# DA1469x register map
Vendor: Dialog; Series: DA1469x; File version: 1.2
CPU: CM33 r1p0, little endian, no MPU, FPU, 3 interrupt priority bits
Registers are 32-bit, read-write, reset 0x0 unless marked. A register's access mark holds for its fields unless they carry their own. Offsets are from the block's base; [hi:lo] are bit positions; {n}, {i} and the like mark numbered series.

## DCDC — DCDC registers
Base 0x50000300
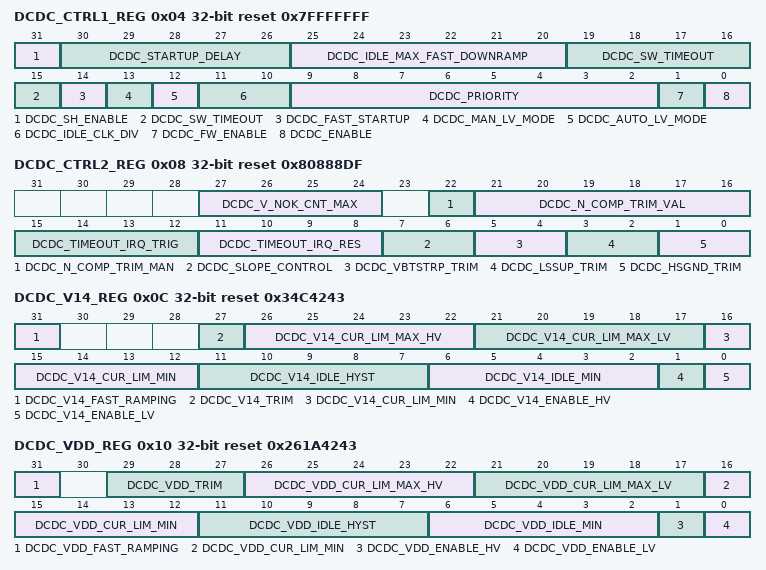
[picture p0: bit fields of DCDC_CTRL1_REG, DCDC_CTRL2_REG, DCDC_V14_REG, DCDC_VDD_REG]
0x04 DCDC_CTRL1_REG reset 0x7FFFFFFF (reset mask 0x7FFFFFFF) — DCDC First Control Register
  [31] DCDC_SH_ENABLE — Enables sample and hold circuit in output comparators.
  [30:26] DCDC_STARTUP_DELAY — Delay between turning bias on and converter becoming active 0 - 31 us, 1 us step size
  [25:20] DCDC_IDLE_MAX_FAST_DOWNRAMP — Maximum output idle time for fast current limit downramping. 0 - 7875 ns, 125 ns step size
  [19:15] DCDC_SW_TIMEOUT — P and N switch timeout, if switch is closed longer than this a timeout is generated and the FSM is forced to the next state Writing 0 disables timeout functionality 62.5 - 1937.5 ns, 62.5 ns step size
  [14] DCDC_FAST_STARTUP — Set current limit to maximum during initial startup
  [13] DCDC_MAN_LV_MODE — Manually activates low voltage settings
  [12] DCDC_AUTO_LV_MODE — Switches to low voltage settings when battery voltage drops below 2.5 V
  [11:10] DCDC_IDLE_CLK_DIV — Idle Clock Divider 00 = 2 01 = 4 10 = 8 11 = 16
  [9:2] DCDC_PRIORITY — Charge priority register (4x 2 bit ID) Charge sequence is [1:0] > [3:2] > [5:4] > [7:6] V14 = 00 V18 = 01 VDD = 10 V18P = 11
  [1] DCDC_FW_ENABLE — Freewheel switch enable
  [0] DCDC_ENABLE — Enable setting for DCDC converter
0x08 DCDC_CTRL2_REG reset 0x80888DF — DCDC Second Control Register
  [27:24] DCDC_V_NOK_CNT_MAX — Maximum number of V_NOK events on an output before V_AVAILABLE is reset
  [22] DCDC_N_COMP_TRIM_MAN — Enables manual trimming for N side comparator
  [21:16] DCDC_N_COMP_TRIM_VAL — Manual trim value for N side comparator Signed magnitude representation 011111 = +13 mV 000000 = 100000 = -22 mV 111111 = -56 mV
  [15:12] DCDC_TIMEOUT_IRQ_TRIG — Number of timeout events before timeout interrupt is generated
  [11:8] DCDC_TIMEOUT_IRQ_RES — Number of successive non-timed out charge events required to clear timeout event counter
  [7:6] DCDC_SLOPE_CONTROL — Sets strength of N and P switch drivers
  [5:4] DCDC_VBTSTRP_TRIM — Trim bootstrap voltage V = 1.6 V + 100 mV * N
  [3:2] DCDC_LSSUP_TRIM — Trim low side supply voltage V = 2 V + 300 mV * N
  [1:0] DCDC_HSGND_TRIM — Trim high side ground V = VBAT - (2 V + 400 mV * N)
0x0C DCDC_V14_REG reset 0x34C4243 (reset mask 0x7FFFFFFF) — DCDC V14 Control Register
  [31] DCDC_V14_FAST_RAMPING — Fast current ramping (improves response time at the cost of more ripple)
  [27] DCDC_V14_TRIM — Output voltage trim Steps of 25 mV
  [26:22] DCDC_V14_CUR_LIM_MAX_HV — Mximum current limit (high battery voltage mode) I = 30 mA * (1 + N)
  [21:17] DCDC_V14_CUR_LIM_MAX_LV — Maximum current limit (low battery voltage mode) I = 30 mA * (1 + N)
  [16:12] DCDC_V14_CUR_LIM_MIN — Minimum current limit I = 30 mA * (1 + N)
  [11:7] DCDC_V14_IDLE_HYST — Idle time hysteresis 0 - 3875 ns, 125 ns step size IDLE_MAX = IDLE_MIN + IDLE_HYST Maximum idle time before decreasing CUR_LIM
  [6:2] DCDC_V14_IDLE_MIN — Minimum idle time 0 - 3875 ns, 125 ns step size Minimum idle time, CUR_LIM is increased if this limit is not reached
  [1] DCDC_V14_ENABLE_HV — Output enable (high battery voltage mode) 0 = Disabled 1 = Enabled
  [0] DCDC_V14_ENABLE_LV — Output enable (low battery voltage mode) 0 = Disabled 1 = Enabled
0x10 DCDC_VDD_REG reset 0x261A4243 (reset mask 0x7FFFFFFF) — DCDC VDD Control Register
  [31] DCDC_VDD_FAST_RAMPING — Fast current ramping (improves response time at the cost of more ripple)
  [29:27] DCDC_VDD_TRIM — Output voltage trim Steps of 25 mV
  [26:22] DCDC_VDD_CUR_LIM_MAX_HV — Maximum current limit (high battery voltage mode) I = 30 mA * (1 + N)
  [21:17] DCDC_VDD_CUR_LIM_MAX_LV — Maximum current limit (low battery voltage mode) I = 30 mA * (1 + N)
  [16:12] DCDC_VDD_CUR_LIM_MIN — Minimum current limit I = 30 mA * (1 + N)
  [11:7] DCDC_VDD_IDLE_HYST — Idle time hysteresis 0 - 3875 ns, 125 ns step size IDLE_MAX = IDLE_MIN + IDLE_HYST Maximum idle time before decreasing CUR_LIM
  [6:2] DCDC_VDD_IDLE_MIN — Minimum idle time 0 - 3875 ns, 125 ns step size Minimum idle time, CUR_LIM is increased if this limit is not reached
  [1] DCDC_VDD_ENABLE_HV — Output enable (high battery voltage mode) 0 = Disabled 1 = Enabled
  [0] DCDC_VDD_ENABLE_LV — Output enable (low battery voltage mode) 0 = Disabled 1 = Enabled
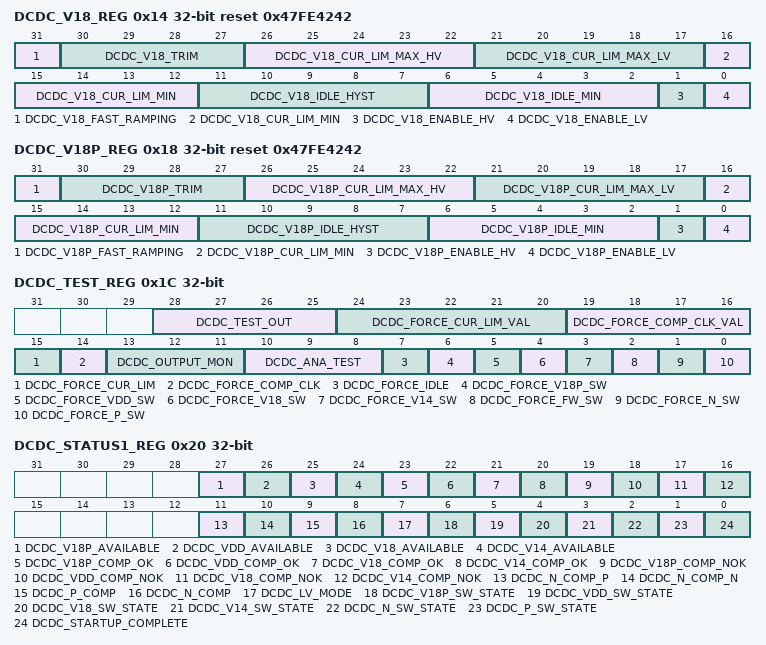
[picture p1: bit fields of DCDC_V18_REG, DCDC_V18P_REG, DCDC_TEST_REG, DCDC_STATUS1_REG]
0x14 DCDC_V18_REG reset 0x47FE4242 (reset mask 0x7FFFFFFF) — DCDC V18 Control Register
  [31] DCDC_V18_FAST_RAMPING — Fast current ramping (improves response time at the cost of more ripple)
  [30:27] DCDC_V18_TRIM — Output voltage trim Steps of 25 mV
  [26:22] DCDC_V18_CUR_LIM_MAX_HV — Maximum current limit (high battery voltage mode) I = 30 mA * (1 + N)
  [21:17] DCDC_V18_CUR_LIM_MAX_LV — Maximum current limit (low battery voltage mode) I = 30 mA * (1 + N)
  [16:12] DCDC_V18_CUR_LIM_MIN — Minimum current limit I = 30 mA * (1 + N)
  [11:7] DCDC_V18_IDLE_HYST — Idle time hysteresis 0 - 3875 ns, 125 ns step size IDLE_MAX = IDLE_MIN + IDLE_HYST Maximum idle time before decreasing CUR_LIM
  [6:2] DCDC_V18_IDLE_MIN — Minimum idle time 0 - 3875 ns, 125 ns step size Minimum idle time, CUR_LIM is increased if this limit is not reached
  [1] DCDC_V18_ENABLE_HV — Output enable (high battery voltage mode) 0 = Disabled 1 = Enabled
  [0] DCDC_V18_ENABLE_LV — Output enable (low battery voltage mode) 0 = Disabled 1 = Enabled
0x18 DCDC_V18P_REG reset 0x47FE4242 (reset mask 0x7FFFFFFF) — DCDC V18P Control Register
  [31] DCDC_V18P_FAST_RAMPING — Fast current ramping (improves response time at the cost of more ripple)
  [30:27] DCDC_V18P_TRIM — Output voltage trim Steps of 25 mV
  [26:22] DCDC_V18P_CUR_LIM_MAX_HV — Maximum current limit (high battery voltage mode) I = 30 mA * (1 + N)
  [21:17] DCDC_V18P_CUR_LIM_MAX_LV — Maximum current limit (low battery voltage mode) I = 30 mA * (1 + N)
  [16:12] DCDC_V18P_CUR_LIM_MIN — Minimum current limit I = 30 mA * (1 + N)
  [11:7] DCDC_V18P_IDLE_HYST — Idle time hysteresis 0 - 3875 ns, 125 ns step size IDLE_MAX = IDLE_MIN + IDLE_HYST Maximum idle time before decreasing CUR_LIM
  [6:2] DCDC_V18P_IDLE_MIN — Minimum idle time 0 - 3875 ns, 125 ns step size Minimum idle time, CUR_LIM is increased if this limit is not reached
  [1] DCDC_V18P_ENABLE_HV — Output enable (high battery voltage mode) 0 = Disabled 1 = Enabled
  [0] DCDC_V18P_ENABLE_LV — Output enable (low battery voltage mode) 0 = Disabled 1 = Enabled
0x1C DCDC_TEST_REG — DCDC Test Register
  [28:25] DCDC_TEST_OUT — Selects which register appears on the test mode pins 0 = None 1 = DCDC_STATUS_1 High Bits 2 = DCDC_STATUS_1 Low Bits 3 = DCDC_STATUS_2 High Bits 4 = DCDC_STATUS_2 Low Bits 5 = DCDC_STATUS_3 High Bits 6 = DCDC_STATUS_3 Low Bits 7 = DCDC_STATUS_4 Low Bits 8-F = Reserved
  [24:20] DCDC_FORCE_CUR_LIM_VAL — Current limit setting when forced
  [19:16] DCDC_FORCE_COMP_CLK_VAL — Sets clock lines for the output comparators
  [15] DCDC_FORCE_CUR_LIM — Force output current setting
  [14] DCDC_FORCE_COMP_CLK — Disables automatic comparator clock, clock lines values based on FORCE_COMP_CLK_VAL
  [13:11] DCDC_OUTPUT_MON — Output monitor switch (connect to ADC) 000 = None 001 = VDD 010 = V18 011 = V14 100 = V18P 101 = V18F 110 = None 111 = None
  [10:8] DCDC_ANA_TEST — Analog test bus 000 = None 001 = High side ground 010 = Low side supply 011 = Bootstrap voltage 100 = 1.0 V buffer output 101 = None 110 = None 111 = None
  [7] DCDC_FORCE_IDLE — Force idle mode
  [6] DCDC_FORCE_V18P_SW — Force V18P switch on
  [5] DCDC_FORCE_VDD_SW — Force VDD switch on
  [4] DCDC_FORCE_V18_SW — Force V18 switch on
  [3] DCDC_FORCE_V14_SW — Force V14 switch on
  [2] DCDC_FORCE_FW_SW — Force FW switch on
  [1] DCDC_FORCE_N_SW — Force N switch on
  [0] DCDC_FORCE_P_SW — Force P switch on
0x20 DCDC_STATUS1_REG — DCDC First Status Register
  [27] DCDC_V18P_AVAILABLE ro — Indicates whether V18P is available Requires that converter is enabled, output is enabled and V_OK has occured. Reset when too many V_NOK events have occured.
  [26] DCDC_VDD_AVAILABLE ro — Indicates whether VDD is available Requires that converter is enabled, output is enabled and V_OK has occured. Reset when too many V_NOK events have occured.
  [25] DCDC_V18_AVAILABLE ro — Indicates whether V18 is available Requires that converter is enabled, output is enabled and V_OK has occured. Reset when too many V_NOK events have occured.
  [24] DCDC_V14_AVAILABLE ro — Indicates whether V14 is available Requires that converter is enabled, output is enabled and V_OK has occured. Reset when too many V_NOK events have occured.
  [23] DCDC_V18P_COMP_OK ro — OK output of V18P comparator
  [22] DCDC_VDD_COMP_OK ro — OK output of VDD comparator
  [21] DCDC_V18_COMP_OK ro — OK output of V18 comparator
  [20] DCDC_V14_COMP_OK ro — OK output of V14 comparator
  [19] DCDC_V18P_COMP_NOK ro — NOK output of V18P comparator
  [18] DCDC_VDD_COMP_NOK ro — NOK output of VDD comparator
  [17] DCDC_V18_COMP_NOK ro — NOK output of V18 comparator
  [16] DCDC_V14_COMP_NOK ro — NOK output of V14 comparator
  [11] DCDC_N_COMP_P ro — DCDC N side dynamic comparator P output
  [10] DCDC_N_COMP_N ro — DCDC N side dynamic comparator N output
  [9] DCDC_P_COMP ro — DCDC P side continuous time comparator output
  [8] DCDC_N_COMP ro — DCDC N side continuous time comparator output
  [7] DCDC_LV_MODE ro — Indicates if the converter is in low battery voltage mode
  [6] DCDC_V18P_SW_STATE ro — DCDC state machine V18P output
  [5] DCDC_VDD_SW_STATE ro — DCDC state machine VDD output
  [4] DCDC_V18_SW_STATE ro — DCDC state machine V18 output
  [3] DCDC_V14_SW_STATE ro — DCDC state machine V14 output
  [2] DCDC_N_SW_STATE ro — DCDC state machine NSW output
  [1] DCDC_P_SW_STATE ro — DCDC state machine PSW output
  [0] DCDC_STARTUP_COMPLETE ro — Indicates if the converter is enabled and the startup counter has expired (internal biasing settled)
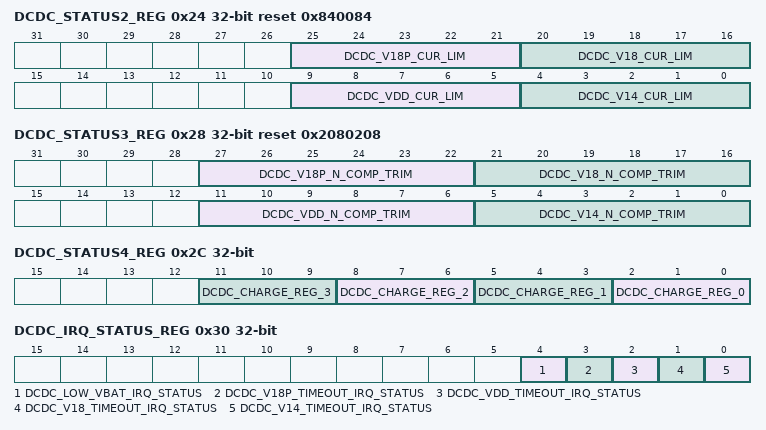
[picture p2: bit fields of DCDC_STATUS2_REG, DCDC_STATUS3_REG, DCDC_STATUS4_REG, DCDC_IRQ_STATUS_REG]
0x24 DCDC_STATUS2_REG reset 0x840084 — DCDC Second Status Register
  [25:21] DCDC_V18P_CUR_LIM ro — Actual V18P current limit
  [20:16] DCDC_V18_CUR_LIM ro — Actual V18 current limit
  [9:5] DCDC_VDD_CUR_LIM ro — Actual VDD current limit
  [4:0] DCDC_V14_CUR_LIM ro — Actual V14 current limit
0x28 DCDC_STATUS3_REG reset 0x2080208 — DCDC Third Status Register
  [27:22] DCDC_V18P_N_COMP_TRIM ro — Actual V18P N side comparator trim value
  [21:16] DCDC_V18_N_COMP_TRIM ro — Actual V18 N side comparator trim value
  [11:6] DCDC_VDD_N_COMP_TRIM ro — Actual VDD N side comparator trim value
  [5:0] DCDC_V14_N_COMP_TRIM ro — Actual V14 N side comparator trim value
0x2C DCDC_STATUS4_REG — DCDC Fourth Status Register
  [3n+2:3n] DCDC_CHARGE_REG_{n} ro (n=0..3) — Charge register position {n}
0x30 DCDC_IRQ_STATUS_REG — DCDC Interrupt Status Register
  [4] DCDC_LOW_VBAT_IRQ_STATUS ro — Low VBAT detector triggered (battery voltage below 2.5 V)
  [3] DCDC_V18P_TIMEOUT_IRQ_STATUS ro — Timeout occured on V18P output
  [2] DCDC_VDD_TIMEOUT_IRQ_STATUS ro — Timeout occured on VDD output
  [1] DCDC_V18_TIMEOUT_IRQ_STATUS ro — Timeout occured on V18 output
  [0] DCDC_V14_TIMEOUT_IRQ_STATUS ro — Timeout occured on V14 output
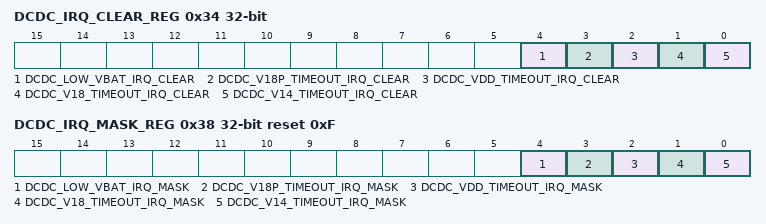
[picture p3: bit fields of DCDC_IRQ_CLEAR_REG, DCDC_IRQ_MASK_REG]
0x34 DCDC_IRQ_CLEAR_REG — DCDC Interrupt Clear Register
  [4] DCDC_LOW_VBAT_IRQ_CLEAR wo — Clear low VBAT interrupt
  [3] DCDC_V18P_TIMEOUT_IRQ_CLEAR wo — Clear V18P timeout interrupt
  [2] DCDC_VDD_TIMEOUT_IRQ_CLEAR wo — Clear VDD timeout interrupt
  [1] DCDC_V18_TIMEOUT_IRQ_CLEAR wo — Clear V18 timeout interrupt
  [0] DCDC_V14_TIMEOUT_IRQ_CLEAR wo — Clear V14 timeout interrupt
0x38 DCDC_IRQ_MASK_REG reset 0xF — DCDC Interrupt Mask Register
  [4] DCDC_LOW_VBAT_IRQ_MASK — Mask low VBAT interrupt
  [3] DCDC_V18P_TIMEOUT_IRQ_MASK — Mask V18P timeout interrupt
  [2] DCDC_VDD_TIMEOUT_IRQ_MASK — Mask VDD timeout interrupt
  [1] DCDC_V18_TIMEOUT_IRQ_MASK — Mask V18 timeout interrupt
  [0] DCDC_V14_TIMEOUT_IRQ_MASK — Mask V14 timeout interrupt
